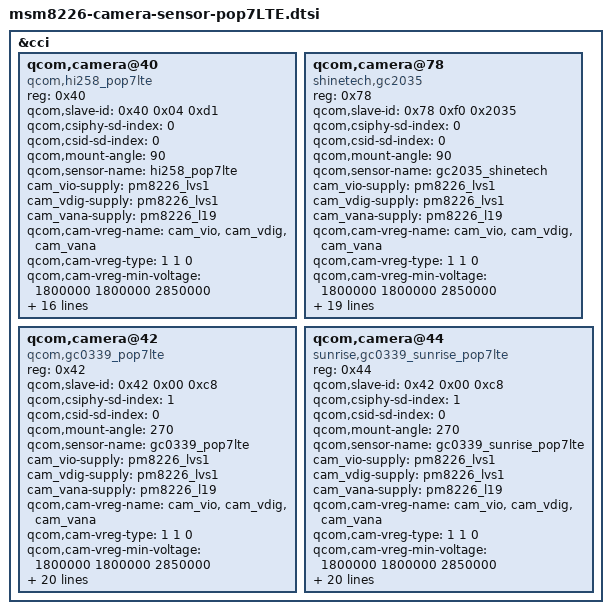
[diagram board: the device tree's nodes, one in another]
/*
 * Copyright (c) 2012-2013, The Linux Foundation. All rights reserved.
 *
 * This program is free software; you can redistribute it and/or modify
 * it under the terms of the GNU General Public License version 2 and
 * only version 2 as published by the Free Software Foundation.
 *
 * This program is distributed in the hope that it will be useful,
 * but WITHOUT ANY WARRANTY; without even the implied warranty of
 * MERCHANTABILITY or FITNESS FOR A PARTICULAR PURPOSE.  See the
 * GNU General Public License for more details.
 */
/*&soc {
	led_flash0: qcom,camera-led-flash {
		cell-index = <0>;
		compatible = "qcom,camera-led-flash";
		qcom,flash-type = <1>;
		qcom,flash-source = <&pm8226_flash0>;
		qcom,torch-source = <&pm8226_torch>;
	};
};*/

&cci {
    qcom,camera@40 {
		compatible = "qcom,hi258_pop7lte";
		reg = <0x40>;
		qcom,slave-id = <0x40 0x04 0xd1>;
		qcom,csiphy-sd-index = <0>;
		qcom,csid-sd-index = <0>;
		/*qcom,led-flash-src = <&led_flash0>;*/
		qcom,mount-angle = <90>;
		qcom,sensor-name = "hi258_pop7lte";
		cam_vio-supply = <&pm8226_lvs1>;
		cam_vdig-supply = <&pm8226_lvs1>;
		cam_vana-supply = <&pm8226_l19>;
		qcom,cam-vreg-name = "cam_vio", "cam_vdig", "cam_vana";
		qcom,cam-vreg-type = <1 1 0>;
		qcom,cam-vreg-min-voltage = <1800000 1800000 2850000>;
		qcom,cam-vreg-max-voltage = <1800000 1800000 2850000>;
		qcom,cam-vreg-op-mode = <200000 0 80000>;
		qcom,gpio-no-mux = <0>;
		gpios = <&msmgpio 26 0>,
		        <&msmgpio 37 0>,
		        <&msmgpio 36 0>;
		qcom,gpio-reset = <1>;
		qcom,gpio-standby = <2>;
		qcom,gpio-req-tbl-num = <0 1 2>;
		qcom,gpio-req-tbl-flags = <1 0 0>;
		qcom,gpio-req-tbl-label = "CAMIF_MCLK",
		        "CAM_RESET",
		        "CAM_STANDBY";
		qcom,csi-lane-assign = <0x4320>;
		qcom,csi-lane-mask = <0x3>;
		qcom,sensor-position = <0>;
		qcom,sensor-mode = <1>;
		qcom,cci-master = <0>;
    };

	qcom,camera@78 {
		compatible = "shinetech,gc2035";
		reg = <0x78>;
		qcom,slave-id = <0x78 0xf0 0x2035>;
		qcom,csiphy-sd-index = <0>;
		qcom,csid-sd-index = <0>;
		qcom,mount-angle = <90>;
		qcom,sensor-name = "gc2035_shinetech";
		cam_vio-supply = <&pm8226_lvs1>;
		cam_vdig-supply = <&pm8226_lvs1>;
		cam_vana-supply = <&pm8226_l19>;
		qcom,cam-vreg-name = "cam_vio", "cam_vdig", "cam_vana";
		qcom,cam-vreg-type = <1 1 0>;
		qcom,cam-vreg-min-voltage = <1800000 1800000 2850000>;
		qcom,cam-vreg-max-voltage = <1800000 1800000 2850000>;
		qcom,cam-vreg-op-mode = <200000 0 80000>;
		qcom,gpio-no-mux = <0>;
		gpios = <&msmgpio 26 0>,
		        <&msmgpio 37 0>,
		        <&msmgpio 36 0>;
		qcom,gpio-reset = <1>;
		qcom,gpio-standby = <2>;
		qcom,gpio-req-tbl-num = <0 1 2>;
		qcom,gpio-req-tbl-flags = <1 0 0>;
		qcom,gpio-req-tbl-label = "CAMIF_MCLK",
				"CAM_RESET",
				"CAM_STANDBY";
		qcom,gpio-set-tbl-num = <1 1>;
		qcom,gpio-set-tbl-flags = <0 2>;
		qcom,gpio-set-tbl-delay = <1000 4000>;
		qcom,csi-lane-assign = <0x4320>;
		qcom,csi-lane-mask = <0x3>;
		qcom,sensor-position = <0>;
		qcom,sensor-mode = <1>;
		qcom,cci-master = <0>;
	    status = "ok";
	};

	qcom,camera@42 {
		compatible = "qcom,gc0339_pop7lte";
		reg = <0x42>;
		qcom,slave-id = <0x42 0x00 0xc8>;
		qcom,csiphy-sd-index = <1>;
		qcom,csid-sd-index = <0>;
		qcom,mount-angle = <270>;
		qcom,sensor-name = "gc0339_pop7lte";
		cam_vio-supply = <&pm8226_lvs1>;
		cam_vdig-supply = <&pm8226_lvs1>;
		cam_vana-supply = <&pm8226_l19>;
		qcom,cam-vreg-name = "cam_vio", "cam_vdig", "cam_vana";
		qcom,cam-vreg-type = <1 1 0>;
		qcom,cam-vreg-min-voltage = <1800000 1800000 2850000>;
		qcom,cam-vreg-max-voltage = <1800000 1800000 2850000>;
		qcom,cam-vreg-op-mode = <200000 0 80000>;
		qcom,gpio-no-mux = <0>;
		gpios = <&msmgpio 26 0>,
				<&msmgpio 28 0>,
				<&msmgpio 35 0>;
		qcom,gpio-reset = <1>;
		qcom,gpio-standby = <2>;
		qcom,gpio-req-tbl-num = <0 1 2>;
		qcom,gpio-req-tbl-flags = <1 0 0>;
		qcom,gpio-req-tbl-label = "CAMIF_MCLK",
				"CAM_RESET",
				"CAM_STANDBY";
		qcom,gpio-set-tbl-num = <1 1>;
		qcom,gpio-set-tbl-flags = <0 2>;
		qcom,gpio-set-tbl-delay = <1000 4000>;
		qcom,csi-lane-assign = <0x4320>;
		qcom,csi-lane-mask = <0x3>;
		qcom,sensor-position = <1>;
		qcom,sensor-mode = <1>;
		qcom,cci-master = <0>;
		status = "ok";
		tct,ctype = <34>;
	};
    
	qcom,camera@44 {
		compatible = "sunrise,gc0339_sunrise_pop7lte";
		reg = <0x44>;
		qcom,slave-id = <0x42 0x00 0xc8>;
		qcom,csiphy-sd-index = <1>;
		qcom,csid-sd-index = <0>;
		qcom,mount-angle = <270>;
		qcom,sensor-name = "gc0339_sunrise_pop7lte";
		cam_vio-supply = <&pm8226_lvs1>;
		cam_vdig-supply = <&pm8226_lvs1>;
		cam_vana-supply = <&pm8226_l19>;
		qcom,cam-vreg-name = "cam_vio", "cam_vdig", "cam_vana";
		qcom,cam-vreg-type = <1 1 0>;
		qcom,cam-vreg-min-voltage = <1800000 1800000 2850000>;
		qcom,cam-vreg-max-voltage = <1800000 1800000 2850000>;
		qcom,cam-vreg-op-mode = <200000 0 80000>;
		qcom,gpio-no-mux = <0>;
		gpios = <&msmgpio 26 0>,
				<&msmgpio 28 0>,
				<&msmgpio 35 0>;
		qcom,gpio-reset = <1>;
		qcom,gpio-standby = <2>;
		qcom,gpio-req-tbl-num = <0 1 2>;
		qcom,gpio-req-tbl-flags = <1 0 0>;
		qcom,gpio-req-tbl-label = "CAMIF_MCLK",
				"CAM_RESET",
				"CAM_STANDBY";
		qcom,gpio-set-tbl-num = <1 1>;
		qcom,gpio-set-tbl-flags = <0 2>;
		qcom,gpio-set-tbl-delay = <1000 4000>;
		qcom,csi-lane-assign = <0x4320>;
		qcom,csi-lane-mask = <0x3>;
		qcom,sensor-position = <1>;
		qcom,sensor-mode = <1>;
		qcom,cci-master = <0>;
		status = "ok";
		tct,ctype = <34>;
	};
};

